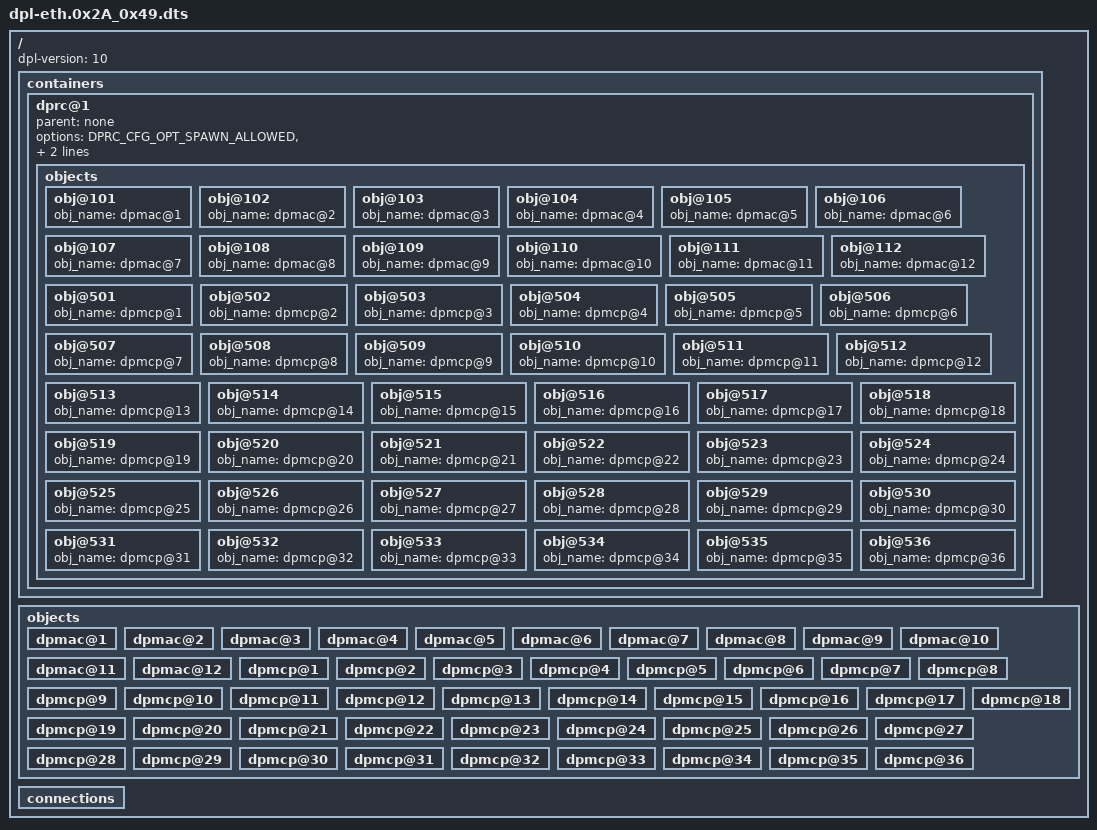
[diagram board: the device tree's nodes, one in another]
/*
 * Copyright 2016 Freescale Semiconductor, Inc.
 */

/dts-v1/;
/ {
	dpl-version = <10>;
	/*****************************************************************
	 * Containers
	 *****************************************************************/
	containers {
		dprc@1 {
			parent = "none";
			options = "DPRC_CFG_OPT_SPAWN_ALLOWED" , "DPRC_CFG_OPT_ALLOC_ALLOWED", "DPRC_CFG_OPT_IRQ_CFG_ALLOWED";

			objects {
				/* ------------- DPMACs --------------*/
				/* For SerDes 0x2a_49, 8 DPMACs are mapped
				 * on the 8 XFI ports and 4 DPMACs
				 * are mapped on the 4 SGMII ports of the PCIe
				 * Slot 4 riser card.
				 */
				obj@101 {
					obj_name = "dpmac@1";
				};
				obj@102 {
					obj_name = "dpmac@2";
				};
				obj@103 {
					obj_name = "dpmac@3";
				};
				obj@104 {
					obj_name = "dpmac@4";
				};
				obj@105 {
					obj_name = "dpmac@5";
				};
				obj@106 {
					obj_name = "dpmac@6";
				};
				obj@107 {
					obj_name = "dpmac@7";
				};
				obj@108 {
					obj_name = "dpmac@8";
				};
				obj@109 {
					obj_name = "dpmac@9";
				};
				obj@110 {
					obj_name = "dpmac@10";
				};
				obj@111 {
					obj_name = "dpmac@11";
				};
				obj@112 {
					obj_name = "dpmac@12";
				};

				/* ------------ DPMCPs --------------*/
				/* Ethernet DPMCPs:
				*  One for every DPNI, one for every DPMAC, then
				*  one more for DPIO.
				*
				*  Next: DPRC and restool, VFIO and possibly
				*  others from the kernel have DPMCP requirements.
				*  We'll just add a slack of 10 MCPs.
				*/
				obj@501 {
					obj_name="dpmcp@1";
				};
				obj@502 {
					obj_name="dpmcp@2";
				};
				obj@503 {
					obj_name="dpmcp@3";
				};
				obj@504 {
					obj_name="dpmcp@4";
				};
				obj@505 {
					obj_name="dpmcp@5";
				};
				obj@506 {
					obj_name="dpmcp@6";
				};
				obj@507 {
					obj_name="dpmcp@7";
				};
				obj@508 {
					obj_name="dpmcp@8";
				};
				obj@509 {
					obj_name="dpmcp@9";
				};
				obj@510 {
					obj_name="dpmcp@10";
				};
				obj@511 {
					obj_name="dpmcp@11";
				};
				obj@512 {
					obj_name="dpmcp@12";
				};
				obj@513 {
					obj_name="dpmcp@13";
				};
				obj@514 {
					obj_name="dpmcp@14";
				};
				obj@515 {
					obj_name="dpmcp@15";
				};
				obj@516 {
					obj_name="dpmcp@16";
				};
				obj@517 {
					obj_name="dpmcp@17";
				};
				obj@518 {
					obj_name="dpmcp@18";
				};
				obj@519 {
					obj_name="dpmcp@19";
				};
				obj@520 {
					obj_name="dpmcp@20";
				};
				obj@521 {
					obj_name="dpmcp@21";
				};
				obj@522 {
					obj_name="dpmcp@22";
				};
				obj@523 {
					obj_name="dpmcp@23";
				};
				obj@524 {
					obj_name="dpmcp@24";
				};
				obj@525 {
					obj_name="dpmcp@25";
				};
				obj@526 {
					obj_name="dpmcp@26";
				};
				obj@527 {
					obj_name="dpmcp@27";
				};
				obj@528 {
					obj_name="dpmcp@28";
				};
				obj@529 {
					obj_name="dpmcp@29";
				};
				obj@530 {
					obj_name="dpmcp@30";
				};
				obj@531 {
					obj_name="dpmcp@31";
				};
				obj@532 {
					obj_name="dpmcp@32";
				};
				obj@533 {
					obj_name="dpmcp@33";
				};
				obj@534 {
					obj_name="dpmcp@34";
				};
				obj@535 {
					obj_name="dpmcp@35";
				};
				obj@536 {
					obj_name="dpmcp@36";
				};
			};
		};
	};

	/*****************************************************************
	 * Objects
	 *****************************************************************/
	objects {
		/* ------------ DPMAC --------------*/
		dpmac@1 {
		};
		dpmac@2 {
		};
		dpmac@3 {
		};
		dpmac@4 {
		};
		dpmac@5 {
		};
		dpmac@6 {
		};
		dpmac@7 {
		};
		dpmac@8 {
		};
		dpmac@9 {
		};
		dpmac@10 {
		};
		dpmac@11 {
		};
		dpmac@12 {
		};

		/* ------------ DPMCP --------------*/
		dpmcp@1 {
		};
		dpmcp@2 {
		};
		dpmcp@3 {
		};
		dpmcp@4 {
		};
		dpmcp@5 {
		};
		dpmcp@6 {
		};
		dpmcp@7 {
		};
		dpmcp@8 {
		};
		dpmcp@9 {
		};
		dpmcp@10 {
		};
		dpmcp@11 {
		};
		dpmcp@12 {
		};
		dpmcp@13 {
		};
		dpmcp@14 {
		};
		dpmcp@15 {
		};
		dpmcp@16 {
		};
		dpmcp@17 {
		};
		dpmcp@18 {
		};
		dpmcp@19 {
		};
		dpmcp@20 {
		};
		dpmcp@21 {
		};
		dpmcp@22 {
		};
		dpmcp@23 {
		};
		dpmcp@24 {
		};
		dpmcp@25 {
		};
		dpmcp@26 {
		};
		dpmcp@27 {
		};
		dpmcp@28 {
		};
		dpmcp@29 {
		};
		dpmcp@30 {
		};
		dpmcp@31 {
		};
		dpmcp@32 {
		};
		dpmcp@33 {
		};
		dpmcp@34 {
		};
		dpmcp@35 {
		};
		dpmcp@36 {
		};
	};

	/*****************************************************************
	 * Connections
	 *****************************************************************/
	connections {
	};
};
